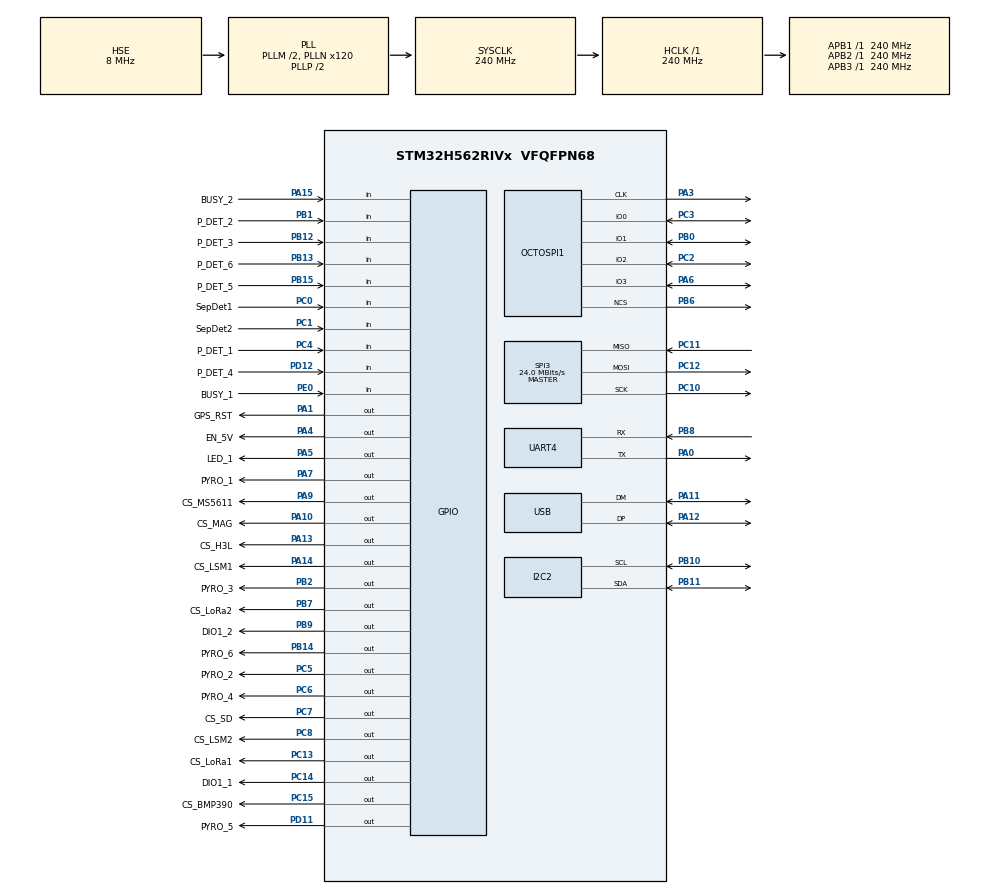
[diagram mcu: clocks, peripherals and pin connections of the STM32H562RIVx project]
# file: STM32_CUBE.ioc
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CORTEX_M33_NS.Number-Cortex_Memory_Protection_Unit_Region0_OTP_RO_AREAS_Settings=MPU_REGION_NUMBER0
CORTEX_M33_NS.default_mode_Activation=1
CORTEX_M33_NS.userName=CORTEX_M33
I2C2.Timing=0x608087CA
Mcu.Family=STM32H5
Mcu.Name=STM32H562RIVx
Mcu.Package=VFQFPN68
NVIC.PriorityGroup=NVIC_PRIORITYGROUP_4
PA0.Mode=Asynchronous
PA0.Signal=UART4_TX
PA1.GPIO_Label=GPS_RST
PA1.Signal=GPIO_Output
PA10.GPIO_Label=CS_MAG
PA10.Signal=GPIO_Output
PA11.Mode=Device
PA11.Signal=USB_DM
PA12.Mode=Device
PA12.Signal=USB_DP
PA13(JTMS/SWDIO).GPIO_Label=CS_H3L
PA13(JTMS/SWDIO).Signal=GPIO_Output
PA14(JTCK/SWCLK).GPIO_Label=CS_LSM1
PA14(JTCK/SWCLK).Signal=GPIO_Output
PA15(JTDI).GPIO_Label=BUSY_2
PA15(JTDI).Signal=GPIO_Input
PA3.Mode=quad_mode
PA3.Signal=OCTOSPI1_CLK
PA4.GPIO_Label=EN_5V
PA4.Signal=GPIO_Output
PA5.GPIO_Label=LED_1
PA5.Signal=GPIO_Output
PA6.Mode=OCTOSPI1_IO[3\:0]
PA6.Signal=OCTOSPI1_IO3
PA7.GPIO_Label=PYRO_1
PA7.Signal=GPIO_Output
PA9.GPIO_Label=CS_MS5611
PA9.Signal=GPIO_Output
PB0.Mode=OCTOSPI1_IO[3\:0]
PB0.Signal=OCTOSPI1_IO1
PB1.GPIO_Label=P_DET_2
PB1.Signal=GPIO_Input
PB10.Mode=I2C
PB10.Signal=I2C2_SCL
PB11.Mode=I2C
PB11.Signal=I2C2_SDA
PB12.GPIO_Label=P_DET_3
PB12.Signal=GPIO_Input
PB13.GPIO_Label=P_DET_6
PB13.Signal=GPIO_Input
PB14.GPIO_Label=PYRO_6
PB14.Signal=GPIO_Output
PB15.GPIO_Label=P_DET_5
PB15.Signal=GPIO_Input
PB2.GPIO_Label=PYRO_3
PB2.Signal=GPIO_Output
PB6.Mode=quad_mode
PB6.Signal=OCTOSPI1_NCS
PB7.GPIO_Label=CS_LoRa2
PB7.Signal=GPIO_Output
PB8.Mode=Asynchronous
PB8.Signal=UART4_RX
PB9.GPIO_Label=DIO1_2
PB9.Signal=GPIO_Output
PC0.GPIO_Label=SepDet1
PC0.Signal=GPIO_Input
PC1.GPIO_Label=SepDet2
PC1.Signal=GPIO_Input
PC10.Mode=Full_Duplex_Master
PC10.Signal=SPI3_SCK
PC11.Mode=Full_Duplex_Master
PC11.Signal=SPI3_MISO
PC12.Mode=Full_Duplex_Master
PC12.Signal=SPI3_MOSI
PC13.GPIO_Label=CS_LoRa1
PC13.Signal=GPIO_Output
PC14-OSC32_IN(OSC32_IN).GPIO_Label=DIO1_1
PC14-OSC32_IN(OSC32_IN).Signal=GPIO_Output
PC15-OSC32_OUT(OSC32_OUT).GPIO_Label=CS_BMP390
PC15-OSC32_OUT(OSC32_OUT).Signal=GPIO_Output
PC2.Mode=OCTOSPI1_IO[3\:0]
PC2.Signal=OCTOSPI1_IO2
PC3.Mode=OCTOSPI1_IO[3\:0]
PC3.Signal=OCTOSPI1_IO0
PC4.GPIO_Label=P_DET_1
PC4.Signal=GPIO_Input
PC5.GPIO_Label=PYRO_2
PC5.Signal=GPIO_Output
PC6.GPIO_Label=PYRO_4
PC6.Signal=GPIO_Output
PC7.GPIO_Label=CS_SD
PC7.Signal=GPIO_Output
PC8.GPIO_Label=CS_LSM2
PC8.Signal=GPIO_Output
PD11.GPIO_Label=PYRO_5
PD11.Signal=GPIO_Output
PD12.GPIO_Label=P_DET_4
PD12.Signal=GPIO_Input
PE0.GPIO_Label=BUSY_1
PE0.Signal=GPIO_Input
PH0-OSC_IN(PH0).Mode=HSE-External-Oscillator
PH0-OSC_IN(PH0).Signal=RCC_OSC_IN
PH1-OSC_OUT(PH1).Mode=HSE-External-Oscillator
PH1-OSC_OUT(PH1).Signal=RCC_OSC_OUT
ProjectManager.HeapSize=0x200
ProjectManager.StackSize=0x400
ProjectManager.TargetToolchain=STM32CubeIDE
RCC.ADCFreq_Value=240000000
RCC.AHBFreq_Value=240000000
RCC.APB1Freq_Value=240000000
RCC.APB1TimFreq_Value=240000000
RCC.APB2Freq_Value=240000000
RCC.APB2TimFreq_Value=240000000
RCC.APB3Freq_Value=240000000
RCC.CSI_VALUE=4000000
RCC.CortexFreq_Value=240000000
RCC.EPOD_VALUE=8000000
RCC.EnbaleCSS=true
RCC.HCLKFreq_Value=240000000
RCC.HSE_VALUE=8000000
RCC.HSI48_VALUE=48000000
RCC.HSI_VALUE=64000000
RCC.LSE_VALUE=32768
RCC.LSIRC_VALUE=32000
RCC.PLL1Q=10
RCC.PLLFRACN=0
RCC.PLLM=2
RCC.PLLN=120
RCC.PLLSourceVirtual=RCC_PLL1_SOURCE_HSE
RCC.SYSCLKFreq_VALUE=240000000
RCC.SYSCLKSource=RCC_SYSCLKSOURCE_PLLCLK
RCC.USBCLockSelection=RCC_USBCLKSOURCE_PLL1Q
RCC.USBFreq_Value=48000000
RCC.VCOOutputFreq_Value=480000000
SPI3.CalculateBaudRate=24.0 MBits/s
SPI3.Direction=SPI_DIRECTION_2LINES
SPI3.Mode=SPI_MODE_MASTER
SPI3.VirtualType=VM_MASTER
USB.VirtualMode=Device_Only
USBX.Core_System=1
USBX.USBD_CDCACM_EPIN_ADDR=2
USBX.USBD_CDCACM_EPOUT_ADDR=3
USBX.UX_DEVICE_CDC_ACM=1
USBX.UX_DEVICE_DFU=1
USBX.UX_DEVICE_ENABLED_FS=1
USBX.UX_Device_CoreStack=1
USBX.UX_enabled_FS=1
VP_BOOTPATH_VS_BOOTPATH.Mode=BP_Activate
VP_CORTEX_M33_NS_VS_Hclk.Mode=Hclk_Mode
VP_ICACHE_VS_ICACHE.Mode=DirectMappedCache
VP_MEMORYMAP_VS_MEMORYMAP.Mode=CurAppReg
VP_PWR_VS_LPOM.Mode=PowerOptimisation
VP_PWR_VS_SECSignals.Mode=Security/Privilege
VP_USBX_Core_System.Mode=Core_System
VP_USBX_UX\ Device\ CDC\ ACM\ Class_FS.Mode=UX_Device_class_CDC_ACM_FS_HS
VP_USBX_UX\ Device\ CoreStack_FS.Mode=UX_Device_CoreStack
VP_USBX_UX\ Device\ DFU_FS.Mode=UX_Device_class_DFU_FS_HS
board=custom

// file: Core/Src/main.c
/* USER CODE BEGIN Header */
/**
  ******************************************************************************
  * @file           : main.c
  * @brief          : Main program body
  ******************************************************************************
  * @attention
  *
  * Copyright (c) 2026 STMicroelectronics.
  * All rights reserved.
  *
  * This software is licensed under terms that can be found in the LICENSE file
  * in the root directory of this software component.
  * If no LICENSE file comes with this software, it is provided AS-IS.
  *
  ******************************************************************************
  */
/* USER CODE END Header */
#include "main.h"
#include "app_usbx.h"

/* USER CODE BEGIN Includes */
#include "flight_computer.h"
/* USER CODE END Includes */

I2C_HandleTypeDef hi2c2;

XSPI_HandleTypeDef hxspi1;

SPI_HandleTypeDef hspi3;

UART_HandleTypeDef huart4;

PCD_HandleTypeDef hpcd_USB_DRD_FS;

void SystemClock_Config(void);
static void MPU_Config(void);
static void MX_GPIO_Init(void);
static void MX_I2C2_Init(void);
static void MX_ICACHE_Init(void);
static void MX_OCTOSPI1_Init(void);
static void MX_SPI3_Init(void);
static void MX_UART4_Init(void);
static void MX_USB_PCD_Init(void);

int main(void)
{

  /* MCU Configuration--------------------------------------------------------*/

  /* MPU Configuration--------------------------------------------------------*/
  MPU_Config();

  /* Reset of all peripherals, Initializes the Flash interface and the Systick. */
  HAL_Init();

  /* Configure the system clock */
  SystemClock_Config();

  /* Initialize all configured peripherals */
  MX_GPIO_Init();
  MX_I2C2_Init();
  MX_ICACHE_Init();
  MX_OCTOSPI1_Init();
  MX_SPI3_Init();
  MX_UART4_Init();
  MX_USB_PCD_Init();
  MX_USBX_Init();
  /* USER CODE BEGIN 2 */
  FlightComputer_Init();
  FlightComputer_Loop();
  /* USER CODE END 2 */

  /* Infinite loop */
  while (1)
  {

  }
}

void SystemClock_Config(void)
{
  RCC_OscInitTypeDef RCC_OscInitStruct = {0};
  RCC_ClkInitTypeDef RCC_ClkInitStruct = {0};

  /** Configure the main internal regulator output voltage
  */
  __HAL_PWR_VOLTAGESCALING_CONFIG(PWR_REGULATOR_VOLTAGE_SCALE0);

  while(!__HAL_PWR_GET_FLAG(PWR_FLAG_VOSRDY)) {}

  /** Initializes the RCC Oscillators according to the specified parameters
  * in the RCC_OscInitTypeDef structure.
  */
  RCC_OscInitStruct.OscillatorType = RCC_OSCILLATORTYPE_HSE;
  RCC_OscInitStruct.HSEState = RCC_HSE_ON;
  RCC_OscInitStruct.PLL.PLLState = RCC_PLL_ON;
  RCC_OscInitStruct.PLL.PLLSource = RCC_PLL1_SOURCE_HSE;
  RCC_OscInitStruct.PLL.PLLM = 2;
  RCC_OscInitStruct.PLL.PLLN = 120;
  RCC_OscInitStruct.PLL.PLLP = 2;
  RCC_OscInitStruct.PLL.PLLQ = 10;
  RCC_OscInitStruct.PLL.PLLR = 2;
  RCC_OscInitStruct.PLL.PLLRGE = RCC_PLL1_VCIRANGE_2;
  RCC_OscInitStruct.PLL.PLLVCOSEL = RCC_PLL1_VCORANGE_WIDE;
  RCC_OscInitStruct.PLL.PLLFRACN = 0;
  if (HAL_RCC_OscConfig(&RCC_OscInitStruct) != HAL_OK)
  {
    Error_Handler();
  }

  /** Initializes the CPU, AHB and APB buses clocks
  */
  RCC_ClkInitStruct.ClockType = RCC_CLOCKTYPE_HCLK|RCC_CLOCKTYPE_SYSCLK
                              |RCC_CLOCKTYPE_PCLK1|RCC_CLOCKTYPE_PCLK2
                              |RCC_CLOCKTYPE_PCLK3;
  RCC_ClkInitStruct.SYSCLKSource = RCC_SYSCLKSOURCE_PLLCLK;
  RCC_ClkInitStruct.AHBCLKDivider = RCC_SYSCLK_DIV1;
  RCC_ClkInitStruct.APB1CLKDivider = RCC_HCLK_DIV1;
  RCC_ClkInitStruct.APB2CLKDivider = RCC_HCLK_DIV1;
  RCC_ClkInitStruct.APB3CLKDivider = RCC_HCLK_DIV1;

  if (HAL_RCC_ClockConfig(&RCC_ClkInitStruct, FLASH_LATENCY_5) != HAL_OK)
  {
    Error_Handler();
  }

  /** Enables the Clock Security System
  */
  HAL_RCC_EnableCSS();

  /** Configure the programming delay
  */
  __HAL_FLASH_SET_PROGRAM_DELAY(FLASH_PROGRAMMING_DELAY_2);
}

static void MX_I2C2_Init(void)
{

  hi2c2.Instance = I2C2;
  hi2c2.Init.Timing = 0x608087CA;
  hi2c2.Init.OwnAddress1 = 0;
  hi2c2.Init.AddressingMode = I2C_ADDRESSINGMODE_7BIT;
  hi2c2.Init.DualAddressMode = I2C_DUALADDRESS_DISABLE;
  hi2c2.Init.OwnAddress2 = 0;
  hi2c2.Init.OwnAddress2Masks = I2C_OA2_NOMASK;
  hi2c2.Init.GeneralCallMode = I2C_GENERALCALL_DISABLE;
  hi2c2.Init.NoStretchMode = I2C_NOSTRETCH_DISABLE;
  if (HAL_I2C_Init(&hi2c2) != HAL_OK)
  {
    Error_Handler();
  }

  /** Configure Analogue filter
  */
  if (HAL_I2CEx_ConfigAnalogFilter(&hi2c2, I2C_ANALOGFILTER_ENABLE) != HAL_OK)
  {
    Error_Handler();
  }

  /** Configure Digital filter
  */
  if (HAL_I2CEx_ConfigDigitalFilter(&hi2c2, 0) != HAL_OK)
  {
    Error_Handler();
  }

}

static void MX_ICACHE_Init(void)
{

  /** Enable instruction cache in 1-way (direct mapped cache)
  */
  if (HAL_ICACHE_ConfigAssociativityMode(ICACHE_1WAY) != HAL_OK)
  {
    Error_Handler();
  }
  if (HAL_ICACHE_Enable() != HAL_OK)
  {
    Error_Handler();
  }

}

static void MX_OCTOSPI1_Init(void)
{

  /* OCTOSPI1 parameter configuration*/
  hxspi1.Instance = OCTOSPI1;
  hxspi1.Init.FifoThresholdByte = 1;
  hxspi1.Init.MemoryMode = HAL_XSPI_SINGLE_MEM;
  hxspi1.Init.MemoryType = HAL_XSPI_MEMTYPE_MICRON;
  hxspi1.Init.MemorySize = HAL_XSPI_SIZE_16B;
  hxspi1.Init.ChipSelectHighTimeCycle = 1;
  hxspi1.Init.FreeRunningClock = HAL_XSPI_FREERUNCLK_DISABLE;
  hxspi1.Init.ClockMode = HAL_XSPI_CLOCK_MODE_0;
  hxspi1.Init.WrapSize = HAL_XSPI_WRAP_NOT_SUPPORTED;
  hxspi1.Init.ClockPrescaler = 0;
  hxspi1.Init.SampleShifting = HAL_XSPI_SAMPLE_SHIFT_NONE;
  hxspi1.Init.DelayHoldQuarterCycle = HAL_XSPI_DHQC_DISABLE;
  hxspi1.Init.ChipSelectBoundary = HAL_XSPI_BONDARYOF_NONE;
  hxspi1.Init.DelayBlockBypass = HAL_XSPI_DELAY_BLOCK_BYPASS;
  hxspi1.Init.Refresh = 0;
  if (HAL_XSPI_Init(&hxspi1) != HAL_OK)
  {
    Error_Handler();
  }

}

static void MX_SPI3_Init(void)
{

  /* SPI3 parameter configuration*/
  hspi3.Instance = SPI3;
  hspi3.Init.Mode = SPI_MODE_MASTER;
  hspi3.Init.Direction = SPI_DIRECTION_2LINES;
  hspi3.Init.DataSize = SPI_DATASIZE_4BIT;
  hspi3.Init.CLKPolarity = SPI_POLARITY_LOW;
  hspi3.Init.CLKPhase = SPI_PHASE_1EDGE;
  hspi3.Init.NSS = SPI_NSS_SOFT;
  hspi3.Init.BaudRatePrescaler = SPI_BAUDRATEPRESCALER_2;
  hspi3.Init.FirstBit = SPI_FIRSTBIT_MSB;
  hspi3.Init.TIMode = SPI_TIMODE_DISABLE;
  hspi3.Init.CRCCalculation = SPI_CRCCALCULATION_DISABLE;
  hspi3.Init.CRCPolynomial = 0x7;
  hspi3.Init.NSSPMode = SPI_NSS_PULSE_ENABLE;
  hspi3.Init.NSSPolarity = SPI_NSS_POLARITY_LOW;
  hspi3.Init.FifoThreshold = SPI_FIFO_THRESHOLD_01DATA;
  hspi3.Init.MasterSSIdleness = SPI_MASTER_SS_IDLENESS_00CYCLE;
  hspi3.Init.MasterInterDataIdleness = SPI_MASTER_INTERDATA_IDLENESS_00CYCLE;
  hspi3.Init.MasterReceiverAutoSusp = SPI_MASTER_RX_AUTOSUSP_DISABLE;
  hspi3.Init.MasterKeepIOState = SPI_MASTER_KEEP_IO_STATE_DISABLE;
  hspi3.Init.IOSwap = SPI_IO_SWAP_DISABLE;
  hspi3.Init.ReadyMasterManagement = SPI_RDY_MASTER_MANAGEMENT_INTERNALLY;
  hspi3.Init.ReadyPolarity = SPI_RDY_POLARITY_HIGH;
  if (HAL_SPI_Init(&hspi3) != HAL_OK)
  {
    Error_Handler();
  }

}

static void MX_UART4_Init(void)
{

  huart4.Instance = UART4;
  huart4.Init.BaudRate = 115200;
  huart4.Init.WordLength = UART_WORDLENGTH_8B;
  huart4.Init.StopBits = UART_STOPBITS_1;
  huart4.Init.Parity = UART_PARITY_NONE;
  huart4.Init.Mode = UART_MODE_TX_RX;
  huart4.Init.HwFlowCtl = UART_HWCONTROL_NONE;
  huart4.Init.OverSampling = UART_OVERSAMPLING_16;
  huart4.Init.OneBitSampling = UART_ONE_BIT_SAMPLE_DISABLE;
  huart4.Init.ClockPrescaler = UART_PRESCALER_DIV1;
  huart4.AdvancedInit.AdvFeatureInit = UART_ADVFEATURE_NO_INIT;
  if (HAL_UART_Init(&huart4) != HAL_OK)
  {
    Error_Handler();
  }
  if (HAL_UARTEx_SetTxFifoThreshold(&huart4, UART_TXFIFO_THRESHOLD_1_8) != HAL_OK)
  {
    Error_Handler();
  }
  if (HAL_UARTEx_SetRxFifoThreshold(&huart4, UART_RXFIFO_THRESHOLD_1_8) != HAL_OK)
  {
    Error_Handler();
  }
  if (HAL_UARTEx_DisableFifoMode(&huart4) != HAL_OK)
  {
    Error_Handler();
  }

}

static void MX_USB_PCD_Init(void)
{

  hpcd_USB_DRD_FS.Instance = USB_DRD_FS;
  hpcd_USB_DRD_FS.Init.dev_endpoints = 8;
  hpcd_USB_DRD_FS.Init.speed = USBD_FS_SPEED;
  hpcd_USB_DRD_FS.Init.phy_itface = PCD_PHY_EMBEDDED;
  hpcd_USB_DRD_FS.Init.Sof_enable = DISABLE;
  hpcd_USB_DRD_FS.Init.low_power_enable = DISABLE;
  hpcd_USB_DRD_FS.Init.lpm_enable = DISABLE;
  hpcd_USB_DRD_FS.Init.battery_charging_enable = DISABLE;
  hpcd_USB_DRD_FS.Init.vbus_sensing_enable = DISABLE;
  hpcd_USB_DRD_FS.Init.bulk_doublebuffer_enable = DISABLE;
  hpcd_USB_DRD_FS.Init.iso_singlebuffer_enable = DISABLE;
  if (HAL_PCD_Init(&hpcd_USB_DRD_FS) != HAL_OK)
  {
    Error_Handler();
  }

}

static void MX_GPIO_Init(void)
{
  GPIO_InitTypeDef GPIO_InitStruct = {0};

  /* GPIO Ports Clock Enable */
  __HAL_RCC_GPIOC_CLK_ENABLE();
  __HAL_RCC_GPIOH_CLK_ENABLE();
  __HAL_RCC_GPIOA_CLK_ENABLE();
  __HAL_RCC_GPIOB_CLK_ENABLE();
  __HAL_RCC_GPIOD_CLK_ENABLE();
  __HAL_RCC_GPIOE_CLK_ENABLE();

  /*Configure GPIO pin Output Level */
  HAL_GPIO_WritePin(GPIOC, CS_LoRa1_Pin|DIO1_1_Pin|CS_BMP390_Pin|PYRO_2_Pin
                          |PYRO_4_Pin|CS_SD_Pin|CS_LSM2_Pin, GPIO_PIN_RESET);

  /*Configure GPIO pin Output Level */
  HAL_GPIO_WritePin(GPIOA, GPS_RST_Pin|EN_5V_Pin|LED_1_Pin|PYRO_1_Pin
                          |CS_MS5611_Pin|CS_MAG_Pin|CS_H3L_Pin|CS_LSM1_Pin, GPIO_PIN_RESET);

  /*Configure GPIO pin Output Level */
  HAL_GPIO_WritePin(GPIOB, PYRO_3_Pin|PYRO_6_Pin|CS_LoRa2_Pin|DIO1_2_Pin, GPIO_PIN_RESET);

  /*Configure GPIO pin Output Level */
  HAL_GPIO_WritePin(PYRO_5_GPIO_Port, PYRO_5_Pin, GPIO_PIN_RESET);

  /*Configure GPIO pins : CS_LoRa1_Pin DIO1_1_Pin CS_BMP390_Pin PYRO_2_Pin
                           PYRO_4_Pin CS_SD_Pin CS_LSM2_Pin */
  GPIO_InitStruct.Pin = CS_LoRa1_Pin|DIO1_1_Pin|CS_BMP390_Pin|PYRO_2_Pin
                          |PYRO_4_Pin|CS_SD_Pin|CS_LSM2_Pin;
  GPIO_InitStruct.Mode = GPIO_MODE_OUTPUT_PP;
  GPIO_InitStruct.Pull = GPIO_NOPULL;
  GPIO_InitStruct.Speed = GPIO_SPEED_FREQ_LOW;
  HAL_GPIO_Init(GPIOC, &GPIO_InitStruct);

  /*Configure GPIO pins : SepDet1_Pin SepDet2_Pin P_DET_1_Pin */
  GPIO_InitStruct.Pin = SepDet1_Pin|SepDet2_Pin|P_DET_1_Pin;
  GPIO_InitStruct.Mode = GPIO_MODE_INPUT;
  GPIO_InitStruct.Pull = GPIO_NOPULL;
  HAL_GPIO_Init(GPIOC, &GPIO_InitStruct);

  /*Configure GPIO pins : GPS_RST_Pin EN_5V_Pin LED_1_Pin PYRO_1_Pin
                           CS_MS5611_Pin CS_MAG_Pin CS_H3L_Pin CS_LSM1_Pin */
  GPIO_InitStruct.Pin = GPS_RST_Pin|EN_5V_Pin|LED_1_Pin|PYRO_1_Pin
                          |CS_MS5611_Pin|CS_MAG_Pin|CS_H3L_Pin|CS_LSM1_Pin;
  GPIO_InitStruct.Mode = GPIO_MODE_OUTPUT_PP;
  GPIO_InitStruct.Pull = GPIO_NOPULL;
  GPIO_InitStruct.Speed = GPIO_SPEED_FREQ_LOW;
  HAL_GPIO_Init(GPIOA, &GPIO_InitStruct);

  /*Configure GPIO pins : P_DET_2_Pin P_DET_3_Pin P_DET_6_Pin P_DET_5_Pin */
  GPIO_InitStruct.Pin = P_DET_2_Pin|P_DET_3_Pin|P_DET_6_Pin|P_DET_5_Pin;
  GPIO_InitStruct.Mode = GPIO_MODE_INPUT;
  GPIO_InitStruct.Pull = GPIO_NOPULL;
  HAL_GPIO_Init(GPIOB, &GPIO_InitStruct);

  /*Configure GPIO pins : PYRO_3_Pin PYRO_6_Pin CS_LoRa2_Pin DIO1_2_Pin */
  GPIO_InitStruct.Pin = PYRO_3_Pin|PYRO_6_Pin|CS_LoRa2_Pin|DIO1_2_Pin;
  GPIO_InitStruct.Mode = GPIO_MODE_OUTPUT_PP;
  GPIO_InitStruct.Pull = GPIO_NOPULL;
  GPIO_InitStruct.Speed = GPIO_SPEED_FREQ_LOW;
  HAL_GPIO_Init(GPIOB, &GPIO_InitStruct);

  /*Configure GPIO pin : PYRO_5_Pin */
  GPIO_InitStruct.Pin = PYRO_5_Pin;
  GPIO_InitStruct.Mode = GPIO_MODE_OUTPUT_PP;
  GPIO_InitStruct.Pull = GPIO_NOPULL;
  GPIO_InitStruct.Speed = GPIO_SPEED_FREQ_LOW;
  HAL_GPIO_Init(PYRO_5_GPIO_Port, &GPIO_InitStruct);

  /*Configure GPIO pin : P_DET_4_Pin */
  GPIO_InitStruct.Pin = P_DET_4_Pin;
  GPIO_InitStruct.Mode = GPIO_MODE_INPUT;
  GPIO_InitStruct.Pull = GPIO_NOPULL;
  HAL_GPIO_Init(P_DET_4_GPIO_Port, &GPIO_InitStruct);

  /*Configure GPIO pin : BUSY_2_Pin */
  GPIO_InitStruct.Pin = BUSY_2_Pin;
  GPIO_InitStruct.Mode = GPIO_MODE_INPUT;
  GPIO_InitStruct.Pull = GPIO_NOPULL;
  HAL_GPIO_Init(BUSY_2_GPIO_Port, &GPIO_InitStruct);

  /*Configure GPIO pin : BUSY_1_Pin */
  GPIO_InitStruct.Pin = BUSY_1_Pin;
  GPIO_InitStruct.Mode = GPIO_MODE_INPUT;
  GPIO_InitStruct.Pull = GPIO_NOPULL;
  HAL_GPIO_Init(BUSY_1_GPIO_Port, &GPIO_InitStruct);

}

 /* MPU Configuration */

void MPU_Config(void)
{
  MPU_Region_InitTypeDef MPU_InitStruct = {0};
  MPU_Attributes_InitTypeDef MPU_AttributesInit = {0};

  /* Disables the MPU */
  HAL_MPU_Disable();

  /** Initializes and configures the Region 0 and the memory to be protected
  */
  MPU_InitStruct.Enable = MPU_REGION_ENABLE;
  MPU_InitStruct.Number = MPU_REGION_NUMBER0;
  MPU_InitStruct.BaseAddress = 0x08FFF000;
  MPU_InitStruct.LimitAddress = 0x08FFFFFF;
  MPU_InitStruct.AttributesIndex = MPU_ATTRIBUTES_NUMBER0;
  MPU_InitStruct.AccessPermission = MPU_REGION_ALL_RO;
  MPU_InitStruct.DisableExec = MPU_INSTRUCTION_ACCESS_DISABLE;
  MPU_InitStruct.IsShareable = MPU_ACCESS_NOT_SHAREABLE;

  HAL_MPU_ConfigRegion(&MPU_InitStruct);

  /** Initializes and configures the Attribute 0 and the memory to be protected
  */
  MPU_AttributesInit.Number = MPU_ATTRIBUTES_NUMBER0;
  MPU_AttributesInit.Attributes = INNER_OUTER(MPU_NOT_CACHEABLE);

  HAL_MPU_ConfigMemoryAttributes(&MPU_AttributesInit);
  /* Enables the MPU */
  HAL_MPU_Enable(MPU_PRIVILEGED_DEFAULT);

}

void Error_Handler(void)
{
  __disable_irq();
  while (1)
  {
  }
}
